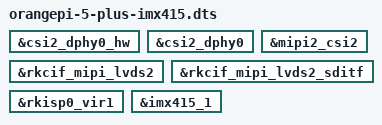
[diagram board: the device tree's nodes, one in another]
/dts-v1/;
/plugin/;

&csi2_dphy0_hw {
	status = "okay";
};

&csi2_dphy0 {
	status = "okay";
};

&mipi2_csi2 {
	status = "okay";
};

&rkcif_mipi_lvds2 {
	status = "okay";
};

&rkcif_mipi_lvds2_sditf {
	status = "okay";
};

&rkisp0_vir1 {
	status = "okay";
};

&imx415_1 {
	status = "okay";
};
